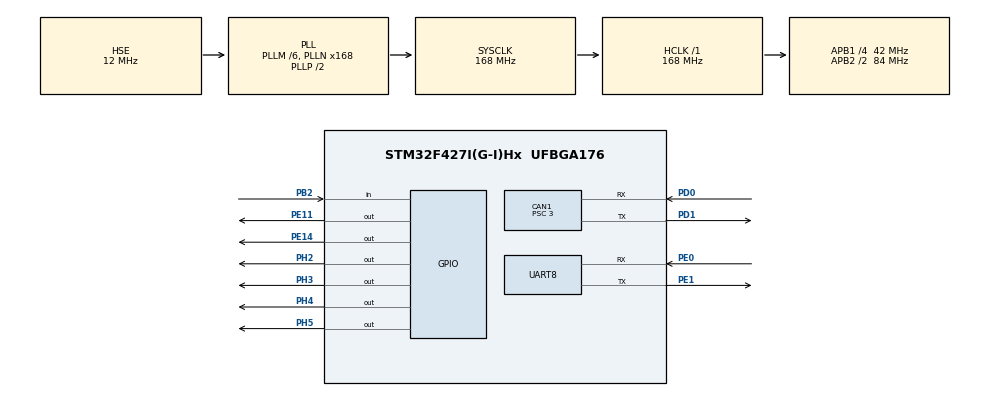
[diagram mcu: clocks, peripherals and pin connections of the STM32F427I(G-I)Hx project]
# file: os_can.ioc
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CAN1.BS1=CAN_BS1_9TQ
CAN1.BS2=CAN_BS2_4TQ
CAN1.CalculateTimeQuantum=71.42857142857143
CAN1.Prescaler=3
FREERTOS.Tasks01=defaultTask,0,128,StartDefaultTask,Default,NULL,Dynamic,NULL,NULL;my6623Task,-3,128,my6623TaskFunction,Default,NULL,Dynamic,NULL,NULL;my2006Task,-3,128,my2006TaskFunction,Default,NULL,Dynamic,NULL,NULL;myLEDTask,-3,128,myLEDTaskFunction,Default,NULL,Dynamic,NULL,NULL
Mcu.Family=STM32F4
Mcu.Name=STM32F427I(G-I)Hx
Mcu.Package=UFBGA176
NVIC.CAN1_RX0_IRQn=true\:0\:0\:false\:false\:true\:true\:true\:true
NVIC.PriorityGroup=NVIC_PRIORITYGROUP_4
NVIC.TIM1_UP_TIM10_IRQn=true\:0\:0\:false\:false\:true\:false\:false\:true
NVIC.TimeBase=TIM1_UP_TIM10_IRQn
NVIC.TimeBaseIP=TIM1
NVIC.UART8_IRQn=true\:0\:0\:false\:false\:true\:false\:true\:true
PB2/BOOT1.Signal=GPIO_Input
PD0.Mode=Master
PD0.Signal=CAN1_RX
PD1.Mode=Master
PD1.Signal=CAN1_TX
PE0.Mode=Asynchronous
PE0.Signal=UART8_RX
PE1.Mode=Asynchronous
PE1.Signal=UART8_TX
PE11.Signal=GPIO_Output
PE14.Signal=GPIO_Output
PH0/OSC_IN.Mode=HSE-External-Oscillator
PH0/OSC_IN.Signal=RCC_OSC_IN
PH1/OSC_OUT.Mode=HSE-External-Oscillator
PH1/OSC_OUT.Signal=RCC_OSC_OUT
PH2.Signal=GPIO_Output
PH3.Signal=GPIO_Output
PH4.Signal=GPIO_Output
PH5.Signal=GPIO_Output
ProjectManager.HeapSize=0x200
ProjectManager.StackSize=0x400
ProjectManager.TargetToolchain=MDK-ARM V5.27
RCC.48MHZClocksFreq_Value=84000000
RCC.AHBFreq_Value=168000000
RCC.APB1CLKDivider=RCC_HCLK_DIV4
RCC.APB1Freq_Value=42000000
RCC.APB1TimFreq_Value=84000000
RCC.APB2CLKDivider=RCC_HCLK_DIV2
RCC.APB2Freq_Value=84000000
RCC.APB2TimFreq_Value=168000000
RCC.CortexFreq_Value=168000000
RCC.HCLKFreq_Value=168000000
RCC.HSE_VALUE=12000000
RCC.HSI_VALUE=16000000
RCC.LSE_VALUE=32768
RCC.PLLM=6
RCC.PLLN=168
RCC.PLLSourceVirtual=RCC_PLLSOURCE_HSE
RCC.SYSCLKFreq_VALUE=168000000
RCC.SYSCLKSource=RCC_SYSCLKSOURCE_PLLCLK
RCC.VCOOutputFreq_Value=336000000
UART8.VirtualMode=Asynchronous
VP_FREERTOS_VS_CMSIS_V1.Mode=CMSIS_V1
VP_SYS_VS_tim1.Mode=TIM1
board=custom

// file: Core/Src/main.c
/* USER CODE BEGIN Header */
/**
  ******************************************************************************
  * @file           : main.c
  * @brief          : Main program body
  ******************************************************************************
  * @attention
  *
  * <h2><center>&copy; Copyright (c) 2020 STMicroelectronics.
  * All rights reserved.</center></h2>
  *
  * This software component is licensed by ST under Ultimate Liberty license
  * SLA0044, the "License"; You may not use this file except in compliance with
  * the License. You may obtain a copy of the License at:
  *                             www.st.com/SLA0044
  *
  ******************************************************************************
  */
/* USER CODE END Header */
#include "main.h"
#include "cmsis_os.h"
#include "can.h"
#include "usart.h"
#include "gpio.h"

void SystemClock_Config(void);
void MX_FREERTOS_Init(void);

int main(void)
{

  /* MCU Configuration--------------------------------------------------------*/

  /* Reset of all peripherals, Initializes the Flash interface and the Systick. */
  HAL_Init();

  /* Configure the system clock */
  SystemClock_Config();

  /* Initialize all configured peripherals */
  MX_GPIO_Init();
  MX_CAN1_Init();
  MX_UART8_Init();
  /* USER CODE BEGIN 2 */
  CAN_FliterInit(&hcan1);

  /* USER CODE END 2 */

  /* Call init function for freertos objects (in freertos.c) */
  MX_FREERTOS_Init();
  /* Start scheduler */
  osKernelStart();

  /* We should never get here as control is now taken by the scheduler */
  /* Infinite loop */
  while (1)
  {

  }
}

void SystemClock_Config(void)
{
  RCC_OscInitTypeDef RCC_OscInitStruct = {0};
  RCC_ClkInitTypeDef RCC_ClkInitStruct = {0};

  /** Configure the main internal regulator output voltage
  */
  __HAL_RCC_PWR_CLK_ENABLE();
  __HAL_PWR_VOLTAGESCALING_CONFIG(PWR_REGULATOR_VOLTAGE_SCALE1);
  /** Initializes the RCC Oscillators according to the specified parameters
  * in the RCC_OscInitTypeDef structure.
  */
  RCC_OscInitStruct.OscillatorType = RCC_OSCILLATORTYPE_HSE;
  RCC_OscInitStruct.HSEState = RCC_HSE_ON;
  RCC_OscInitStruct.PLL.PLLState = RCC_PLL_ON;
  RCC_OscInitStruct.PLL.PLLSource = RCC_PLLSOURCE_HSE;
  RCC_OscInitStruct.PLL.PLLM = 6;
  RCC_OscInitStruct.PLL.PLLN = 168;
  RCC_OscInitStruct.PLL.PLLP = RCC_PLLP_DIV2;
  RCC_OscInitStruct.PLL.PLLQ = 4;
  if (HAL_RCC_OscConfig(&RCC_OscInitStruct) != HAL_OK)
  {
    Error_Handler();
  }
  /** Initializes the CPU, AHB and APB buses clocks
  */
  RCC_ClkInitStruct.ClockType = RCC_CLOCKTYPE_HCLK|RCC_CLOCKTYPE_SYSCLK
                              |RCC_CLOCKTYPE_PCLK1|RCC_CLOCKTYPE_PCLK2;
  RCC_ClkInitStruct.SYSCLKSource = RCC_SYSCLKSOURCE_PLLCLK;
  RCC_ClkInitStruct.AHBCLKDivider = RCC_SYSCLK_DIV1;
  RCC_ClkInitStruct.APB1CLKDivider = RCC_HCLK_DIV4;
  RCC_ClkInitStruct.APB2CLKDivider = RCC_HCLK_DIV2;

  if (HAL_RCC_ClockConfig(&RCC_ClkInitStruct, FLASH_LATENCY_5) != HAL_OK)
  {
    Error_Handler();
  }
}

void HAL_TIM_PeriodElapsedCallback(TIM_HandleTypeDef *htim)
{
  if (htim->Instance == TIM1) {
    HAL_IncTick();
  }
}

void Error_Handler(void)
{
}

/************************ (C) COPYRIGHT STMicroelectronics *****END OF FILE****/

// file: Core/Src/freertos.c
/* USER CODE BEGIN Header */
/**
  ******************************************************************************
  * File Name          : freertos.c
  * Description        : Code for freertos applications
  ******************************************************************************
  * @attention
  *
  * <h2><center>&copy; Copyright (c) 2020 STMicroelectronics.
  * All rights reserved.</center></h2>
  *
  * This software component is licensed by ST under Ultimate Liberty license
  * SLA0044, the "License"; You may not use this file except in compliance with
  * the License. You may obtain a copy of the License at:
  *                             www.st.com/SLA0044
  *
  ******************************************************************************
  */
/* USER CODE END Header */

#include "FreeRTOS.h"
#include "task.h"
#include "main.h"
#include "cmsis_os.h"

/* USER CODE BEGIN Includes */
#include "stdio.h"
#include "can.h"
/* USER CODE END Includes */

osThreadId defaultTaskHandle;
osThreadId my6623TaskHandle;
osThreadId my2006TaskHandle;
osThreadId myLEDTaskHandle;

void StartDefaultTask(void const * argument);
void my6623TaskFunction(void const * argument);
void my2006TaskFunction(void const * argument);
void myLEDTaskFunction(void const * argument);

void MX_FREERTOS_Init(void); /* (MISRA C 2004 rule 8.1) */

/* GetIdleTaskMemory prototype (linked to static allocation support) */
void vApplicationGetIdleTaskMemory( StaticTask_t **ppxIdleTaskTCBBuffer, StackType_t **ppxIdleTaskStackBuffer, uint32_t *pulIdleTaskStackSize );

/* USER CODE BEGIN GET_IDLE_TASK_MEMORY */
static StaticTask_t xIdleTaskTCBBuffer;
static StackType_t xIdleStack[configMINIMAL_STACK_SIZE];

void vApplicationGetIdleTaskMemory( StaticTask_t **ppxIdleTaskTCBBuffer, StackType_t **ppxIdleTaskStackBuffer, uint32_t *pulIdleTaskStackSize )
{
  *ppxIdleTaskTCBBuffer = &xIdleTaskTCBBuffer;
  *ppxIdleTaskStackBuffer = &xIdleStack[0];
  *pulIdleTaskStackSize = configMINIMAL_STACK_SIZE;
  /* place for user code */
}
/* USER CODE END GET_IDLE_TASK_MEMORY */

void MX_FREERTOS_Init(void) {

  /* Create the thread(s) */
  /* definition and creation of defaultTask */
  osThreadDef(defaultTask, StartDefaultTask, osPriorityNormal, 0, 128);
  defaultTaskHandle = osThreadCreate(osThread(defaultTask), NULL);

  /* definition and creation of my6623Task */
  osThreadDef(my6623Task, my6623TaskFunction, osPriorityIdle, 0, 128);
  my6623TaskHandle = osThreadCreate(osThread(my6623Task), NULL);

  /* definition and creation of my2006Task */
  osThreadDef(my2006Task, my2006TaskFunction, osPriorityIdle, 0, 128);
  my2006TaskHandle = osThreadCreate(osThread(my2006Task), NULL);

  /* definition and creation of myLEDTask */
  osThreadDef(myLEDTask, myLEDTaskFunction, osPriorityIdle, 0, 128);
  myLEDTaskHandle = osThreadCreate(osThread(myLEDTask), NULL);

}

void StartDefaultTask(void const * argument)
{
  /* USER CODE BEGIN StartDefaultTask */
  /* Infinite loop */
  for(;;)
  {
    //printf("this is in default task\r\n");
    vTaskDelay(1000);
  }
  /* USER CODE END StartDefaultTask */
}

void my6623TaskFunction(void const * argument)
{
  /* USER CODE BEGIN my6623TaskFunction */
  /* Infinite loop */
  for(;;)
  {
	//printf("this is in 6223 task\r\n");
	set_motor_voltage(0x1ff,0x03E8,0x1f,0x1f,0x1f);
    vTaskDelay(1);
  }
  /* USER CODE END my6623TaskFunction */
}

void my2006TaskFunction(void const * argument)
{
  /* USER CODE BEGIN my2006TaskFunction */
  /* Infinite loop */
  for(;;)
  {
	set_motor_voltage(0x200,0x03E8,0x03E8,0x03E8,0x03E8);
	//printf("this is in 2006 task\r\n");
    vTaskDelay(1);
  }
  /* USER CODE END my2006TaskFunction */
}

void myLEDTaskFunction(void const * argument)
{
  /* USER CODE BEGIN myLEDTaskFunction */
  /* Infinite loop */
  for(;;)
  {
	  vTaskDelay(1);
  }
  /* USER CODE END myLEDTaskFunction */
}

/************************ (C) COPYRIGHT STMicroelectronics *****END OF FILE****/
